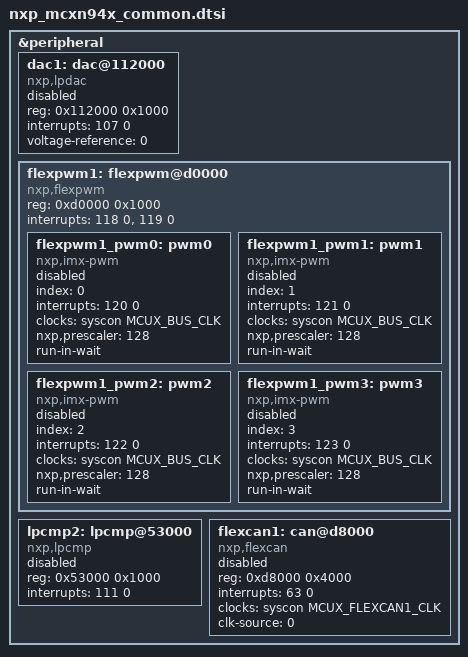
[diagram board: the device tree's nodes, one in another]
/*
 * Copyright 2024-2025 NXP
 *
 * SPDX-License-Identifier: Apache-2.0
 */

#include "nxp_mcxnx4x_common.dtsi"

&peripheral {
	dac1: dac@112000 {
		compatible = "nxp,lpdac";
		reg = <0x112000 0x1000>;
		interrupts = <107 0>;
		status = "disabled";
		voltage-reference = <0>;
		#io-channel-cells = <1>;
	};

	flexpwm1: flexpwm@d0000 {
		compatible = "nxp,flexpwm";
		reg = <0xd0000 0x1000>;
		interrupt-names = "RELOAD-ERROR", "FAULT";
		interrupts = <118 0>, <119 0>;

		flexpwm1_pwm0: pwm0 {
			compatible = "nxp,imx-pwm";
			index = <0>;
			interrupts = <120 0>;
			#pwm-cells = <3>;
			clocks = <&syscon MCUX_BUS_CLK>;
			nxp,prescaler = <128>;
			status = "disabled";
			run-in-wait;
		};

		flexpwm1_pwm1: pwm1 {
			compatible = "nxp,imx-pwm";
			index = <1>;
			interrupts = <121 0>;
			#pwm-cells = <3>;
			clocks = <&syscon MCUX_BUS_CLK>;
			nxp,prescaler = <128>;
			status = "disabled";
			run-in-wait;
		};

		flexpwm1_pwm2: pwm2 {
			compatible = "nxp,imx-pwm";
			index = <2>;
			interrupts = <122 0>;
			#pwm-cells = <3>;
			clocks = <&syscon MCUX_BUS_CLK>;
			nxp,prescaler = <128>;
			status = "disabled";
			run-in-wait;
		};

		flexpwm1_pwm3: pwm3 {
			compatible = "nxp,imx-pwm";
			index = <3>;
			interrupts = <123 0>;
			#pwm-cells = <3>;
			clocks = <&syscon MCUX_BUS_CLK>;
			nxp,prescaler = <128>;
			status = "disabled";
			run-in-wait;
		};
	};

	lpcmp2: lpcmp@53000 {
		compatible = "nxp,lpcmp";
		reg = <0x53000 0x1000>;
		interrupts = <111 0>;
		status = "disabled";
		#io-channel-cells = <2>;
	};

	flexcan1: can@d8000 {
		compatible = "nxp,flexcan";
		reg = <0xd8000 0x4000>;
		interrupts = <63 0>;
		interrupt-names = "common";
		clocks = <&syscon MCUX_FLEXCAN1_CLK>;
		clk-source = <0>;
		status = "disabled";
	};
};
